AUTOSAR XML (schema 4-0-3)
standard types defined: Boolean, UInt16, UInt32
package /AUTOSAR_Platform/DataConstrs
  range DC_Boolean: raw 0..1
  range DC_UInt16: raw 0..65535
package /PATAC/Facility/DataTypes/Implementation
  compu method COMPU_Boolean: 0=FALSE, 1=TRUE
  unit NoUnit: factor-si-to-unit=1, offset-si-to-unit=0
package /PATAC/MSM/ComponentTypes
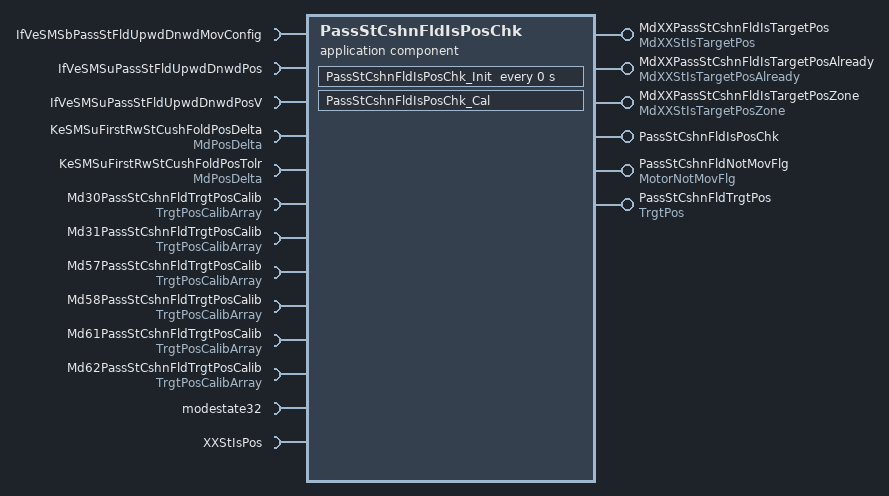
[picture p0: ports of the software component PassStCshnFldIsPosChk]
  application sw component type PassStCshnFldIsPosChk
    6 x provide port:
      MdXXPassStCshnFldIsTargetPos: nonqueued-sender-com-spec{data-element=MdXXStIsTargetPos/Val, init-value=0}, provided-interface=MdXXStIsTargetPos
      MdXXPassStCshnFldIsTargetPosAlready: nonqueued-sender-com-spec{data-element=MdXXStIsTargetPosAlready/Val, init-value=0}, provided-interface=MdXXStIsTargetPosAlready
      MdXXPassStCshnFldIsTargetPosZone: nonqueued-sender-com-spec{data-element=MdXXStIsTargetPosZone/Val, init-value=0}, provided-interface=MdXXStIsTargetPosZone
      PassStCshnFldIsPosChk: server-com-spec{operation=Cal, queue-length=1}, provided-interface=PassStCshnFldIsPosChk
      PassStCshnFldNotMovFlg: nonqueued-sender-com-spec{data-element=MotorNotMovFlg/Val, init-value=0}, provided-interface=MotorNotMovFlg
      PassStCshnFldTrgtPos: nonqueued-sender-com-spec{data-element=TrgtPos/Val, init-value=4095}, provided-interface=TrgtPos
    13 x require port:
      IfVeSMSbPassStFldUpwdDnwdMovConfig: nonqueued-receiver-com-spec{data-element=IfVeSMSbPassStFldUpwdDnwdMovConfig/Val, filter=data-filter-type=ALWAYS, init-value=0}, required-interface=IfVeSMSbPassStFldUpwdDnwdMovConfig
      IfVeSMSuPassStFldUpwdDnwdPos: nonqueued-receiver-com-spec{data-element=IfVeSMSuPassStFldUpwdDnwdPos/Val, filter=data-filter-type=ALWAYS, init-value=0}, required-interface=IfVeSMSuPassStFldUpwdDnwdPos
      IfVeSMSuPassStFldUpwdDnwdPosV: nonqueued-receiver-com-spec{data-element=IfVeSMSuPassStFldUpwdDnwdPosV/Val, filter=data-filter-type=ALWAYS, init-value=0}, required-interface=IfVeSMSuPassStFldUpwdDnwdPosV
      KeSMSuFirstRwStCushFoldPosDelta: parameter-require-com-spec{init-value=150, parameter=Val}, required-interface=MdPosDelta
      KeSMSuFirstRwStCushFoldPosTolr: parameter-require-com-spec{init-value=150, parameter=Val}, required-interface=MdPosDelta
      Md30PassStCshnFldTrgtPosCalib: nonqueued-receiver-com-spec{data-element=TrgtPosArray, filter=data-filter-type=ALWAYS, init-value=[4095, 4095, 4095]}, required-interface=TrgtPosCalibArray
      Md31PassStCshnFldTrgtPosCalib: nonqueued-receiver-com-spec{data-element=TrgtPosArray, filter=data-filter-type=ALWAYS, init-value=[4095, 4095, 4095]}, required-interface=TrgtPosCalibArray
      Md57PassStCshnFldTrgtPosCalib: nonqueued-receiver-com-spec{data-element=TrgtPosArray, filter=data-filter-type=ALWAYS, init-value=[0, 0, 0]}, required-interface=TrgtPosCalibArray
      Md58PassStCshnFldTrgtPosCalib: nonqueued-receiver-com-spec{data-element=TrgtPosArray, filter=data-filter-type=ALWAYS, init-value=[0, 0, 0]}, required-interface=TrgtPosCalibArray
      Md61PassStCshnFldTrgtPosCalib: nonqueued-receiver-com-spec{data-element=TrgtPosArray, filter=data-filter-type=ALWAYS, init-value=[4095, 4095, 4095]}, required-interface=TrgtPosCalibArray
      Md62PassStCshnFldTrgtPosCalib: nonqueued-receiver-com-spec{data-element=TrgtPosArray, filter=data-filter-type=ALWAYS, init-value=[4095, 4095, 4095]}, required-interface=TrgtPosCalibArray
      modestate32: nonqueued-receiver-com-spec{data-element=modestate32/Val, filter=data-filter-type=ALWAYS, init-value=0}, required-interface=modestate32
      XXStIsPos: client-com-spec=Get, required-interface=XXStIsPos
    behavior PassStCshnFldIsPosChk_InternalBehavior
      operation invoked event OIT_PassStCshnFldIsPosChk_Cal_PassStCshnFldIsPosChk_Cal: start-on-event=PassStCshnFldIsPosChk_Cal, operation=PassStCshnFldIsPosChk.Cal
      timing event PassStCshnFldIsPosChk_InitEvent: start-on-event=PassStCshnFldIsPosChk_Init, period=0
      runnable PassStCshnFldIsPosChk_Cal
        data-receive-point-by-arguments:
          10 x access:
            REC_IfVeSMSbPassStFldUpwdDnwdMovConfig_Val: accessed-variable=IfVeSMSbPassStFldUpwdDnwdMovConfig.Val
            REC_IfVeSMSuPassStFldUpwdDnwdPos_Val: accessed-variable=IfVeSMSuPassStFldUpwdDnwdPos.Val
            REC_IfVeSMSuPassStFldUpwdDnwdPosV_Val: accessed-variable=IfVeSMSuPassStFldUpwdDnwdPosV.Val
            REC_Md30PassStCshnFldTrgtPosCalib_TrgtPosArray: accessed-variable=Md30PassStCshnFldTrgtPosCalib.TrgtPosArray
            REC_Md31PassStCshnFldTrgtPosCalib_TrgtPosArray: accessed-variable=Md31PassStCshnFldTrgtPosCalib.TrgtPosArray
            REC_Md57PassStCshnFldTrgtPosCalib_TrgtPosArray: accessed-variable=Md57PassStCshnFldTrgtPosCalib.TrgtPosArray
            REC_Md58PassStCshnFldTrgtPosCalib_TrgtPosArray: accessed-variable=Md58PassStCshnFldTrgtPosCalib.TrgtPosArray
            REC_Md61PassStCshnFldTrgtPosCalib_TrgtPosArray: accessed-variable=Md61PassStCshnFldTrgtPosCalib.TrgtPosArray
            REC_Md62PassStCshnFldTrgtPosCalib_TrgtPosArray: accessed-variable=Md62PassStCshnFldTrgtPosCalib.TrgtPosArray
            REC_modestate32_Val: accessed-variable=modestate32.Val
        data-send-points:
          5 x access:
            SEND_MdXXPassStCshnFldIsTargetPos_Val: accessed-variable=MdXXPassStCshnFldIsTargetPos.Val
            SEND_MdXXPassStCshnFldIsTargetPosAlready_Val: accessed-variable=MdXXPassStCshnFldIsTargetPosAlready.Val
            SEND_MdXXPassStCshnFldIsTargetPosZone_Val: accessed-variable=MdXXPassStCshnFldIsTargetPosZone.Val
            SEND_PassStCshnFldNotMovFlg_Val: accessed-variable=PassStCshnFldNotMovFlg.Val
            SEND_PassStCshnFldTrgtPos_Val: accessed-variable=PassStCshnFldTrgtPos.Val
        parameter access PA_KeSMSuFirstRwStCushFoldPosDelta_Val: accessed-parameter=KeSMSuFirstRwStCushFoldPosDelta.Val
        parameter access PA_KeSMSuFirstRwStCushFoldPosTolr_Val: accessed-parameter=KeSMSuFirstRwStCushFoldPosTolr.Val
        sync call SC_XXStIsPos_Get: operation=XXStIsPos.Get, timeout=0
      runnable PassStCshnFldIsPosChk_Init
        parameter access PA_KeSMSuFirstRwStCushFoldPosDelta_Val: accessed-parameter=KeSMSuFirstRwStCushFoldPosDelta.Val
        parameter access PA_KeSMSuFirstRwStCushFoldPosTolr_Val: accessed-parameter=KeSMSuFirstRwStCushFoldPosTolr.Val
  swc implementation PassStCshnFldIsPosChk_Implementation: behavior=PassStCshnFldIsPosChk_InternalBehavior
    code-descriptors:
      code Default: artifact-descriptors=autosar-engineering-object={short-label=Default, category=SWSRC}
package /PATAC/MSM/ModeAdjust/CalPortInterface
  parameter interface MdPosDelta
    parameter data prototype Val: sw-calibration-access=READ-WRITE, type=UInt16
package /PATAC/MSM/ModeAdjust/DataType
  impl type TrgtPosCalibArray: category=ARRAY, sw-calibration-access=READ-ONLY, type-emitter=RTE  # 0:pos 1:max 2:min
    element Element: array-size=3, array-size-semantics=FIXED-SIZE, implementation-data-type=UInt16, invalid-value=0
package /PATAC/MSM/ModeAdjust/Interfaces
  sender receiver interface IfVeSMSuPassStFldUpwdDnwdPosV: invalidation-policy{data-element=IfVeSMSuPassStFldUpwdDnwdPosV/Val, handle-invalid=DONT-INVALIDATE}
    data Val: type=Implementation/Boolean
package /PATAC/MSM/ModeAdjust/PortInterface
  client server interface PassStCshnFldIsPosChk
    operation Cal
  client server interface XXStIsPos
    operation Get
      8 x arg, all with server-argument-impl-policy=USE-ARGUMENT-TYPE:
        PosV: type=DataTypes/Boolean, direction=IN
        Pos: type=UInt16, direction=IN
        CalibArray: type=TrgtPosCalibArray, direction=IN
        Delta: type=UInt16, direction=IN
        Tolr: type=UInt16, direction=IN
        IsPos: type=DataTypes/Boolean, direction=OUT
        IsPosZone: type=DataTypes/Boolean, direction=OUT
        IsPosAlready: type=DataTypes/Boolean, direction=OUT
  8 x sender receiver interface:
    IfVeSMSbPassStFldUpwdDnwdMovConfig: invalidation-policy{data-element=IfVeSMSbPassStFldUpwdDnwdMovConfig/Val, handle-invalid=DONT-INVALIDATE}
      data Val: type=Implementation/Boolean
    IfVeSMSuPassStFldUpwdDnwdPos: invalidation-policy{data-element=IfVeSMSuPassStFldUpwdDnwdPos/Val, handle-invalid=DONT-INVALIDATE}
      data Val: type=UInt16
    MdXXStIsTargetPos: invalidation-policy{data-element=MdXXStIsTargetPos/Val, handle-invalid=DONT-INVALIDATE}
      data Val: type=UInt32
    MdXXStIsTargetPosAlready: invalidation-policy{data-element=MdXXStIsTargetPosAlready/Val, handle-invalid=DONT-INVALIDATE}
      data Val: type=UInt32
    MdXXStIsTargetPosZone: invalidation-policy{data-element=MdXXStIsTargetPosZone/Val, handle-invalid=DONT-INVALIDATE}
      data Val: type=UInt32
    modestate32: invalidation-policy{data-element=modestate32/Val, handle-invalid=DONT-INVALIDATE}
      data Val: type=UInt32
    MotorNotMovFlg: invalidation-policy{data-element=MotorNotMovFlg/Val, handle-invalid=DONT-INVALIDATE}
      data Val: type=Implementation/Boolean
    TrgtPosCalibArray: invalidation-policy{data-element=TrgtPosArray, handle-invalid=DONT-INVALIDATE}
      data TrgtPosArray: type=TrgtPosCalibArray  # 0:Pos 1:Max 2:Min
package /PATAC/MSM/PortInterfaces
  sender receiver interface TrgtPos: invalidation-policy{data-element=TrgtPos/Val, handle-invalid=DONT-INVALIDATE}
    data Val: type=UInt16
